# CH32V205 register map
Vendor: WCH Ltd.; File version: 1.0
Registers are 32-bit, read-write, reset 0x0 unless marked. A register's access mark holds for its fields unless they carry their own. Offsets are from the block's base; [hi:lo] are bit positions; {n}, {i} and the like mark numbered series.

## FLASH
Base 0x40022000
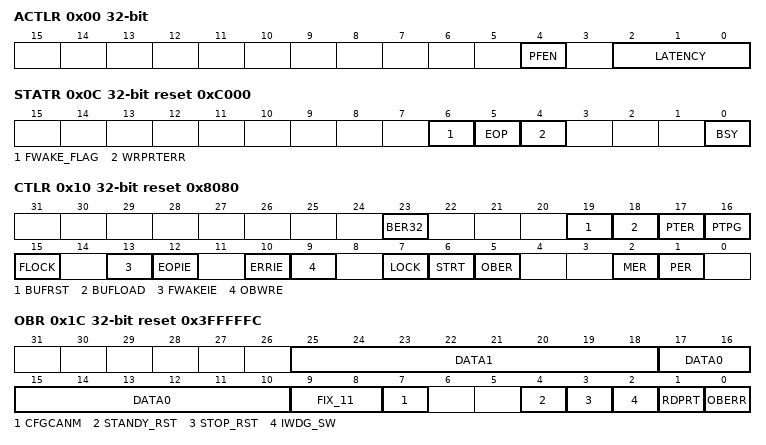
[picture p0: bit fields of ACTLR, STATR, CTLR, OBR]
0x00 ACTLR — Access control register
  [4] PFEN — prefetch enable
  [2:0] LATENCY — FLASH standby condition
0x04 KEYR wo reset 0x3FFFFFC — Flash key register
  [31:0] KEYR — FPEC key
0x08 OBKEYR wo — Flash option key register
  [31:0] OBTKEY — Option byte key
0x0C STATR access per field reset 0xC000 — Status register
  [6] FWAKE_FLAG rw — Wake-Up flag
  [5] EOP rw — End of operation
  [4] WRPRTERR rw — Write protection error
  [0] BSY ro — Busy
0x10 CTLR reset 0x8080 — Control register
  [23] BER32 — Block Erase 32K
  [19] BUFRST — BUF reset
  [18] BUFLOAD — Data buffer
  [17] PTER — Fast erase
  [16] PTPG — Fast programming
  [15] FLOCK — Fast programmable lock
  [13] FWAKEIE — wake-up interrupt enable
  [12] EOPIE — End of operation interrupt enable
  [10] ERRIE — Error interrupt enable
  [9] OBWRE — Option bytes write enable
  [7] LOCK
  [6] STRT — Start
  [5] OBER — Option byte erase
  [2] MER — Mass Erase
  [1] PER — Page Erase
0x14 ADDR wo — Flash address register
  [31:0] FAR — Flash Address
0x1C OBR ro reset 0x3FFFFFC — Option byte register
  [25:18] DATA1 — Data byte 1
  [17:10] DATA0 — Data byte 0
  [9:8] FIX_11 — Fixed to 11
  [7] CFGCANM — Configure the offline recovery time
  [4] STANDY_RST
  [3] STOP_RST
  [2] IWDG_SW
  [1] RDPRT — Read protection
  [0] OBERR — Option byte error
0x20 WPR ro — Write protection register
  [31:0] WRP — Write protect
0x24 MODEKEYR wo reset 0xFFE — Mode select register
  [31:0] MODEKEYR — Mode select

## PFIC — Programmable Fast Interrupt Controller
Base 0xE000E000
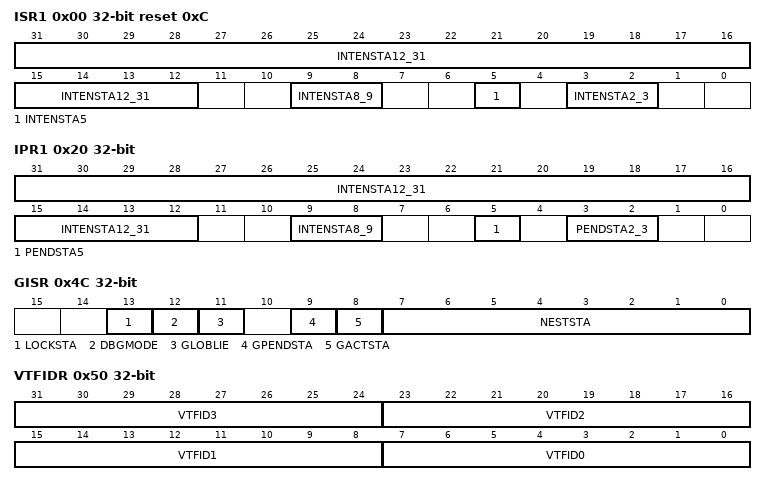
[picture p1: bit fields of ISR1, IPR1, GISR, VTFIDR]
0x00 ISR1 ro reset 0xC — Interrupt Status Register
  [31:12] INTENSTA12_31 — Interrupt ID Status
  [9:8] INTENSTA8_9 — Interrupt ID Status
  [5] INTENSTA5 — Interrupt ID Status
  [3:2] INTENSTA2_3 — Interrupt ID Status
0x04 ISR2 ro — Interrupt Status Register
  [31:0] INTENSTA — Interrupt ID Status
0x08 ISR3 ro — Interrupt Status Register
  [20:0] INTENSTA — Interrupt ID Status
0x20 IPR1 ro — Interrupt Pending Register
  [31:12] INTENSTA12_31 — PENDSTA
  [9:8] INTENSTA8_9 — PENDSTA
  [5] PENDSTA5 — PENDSTA
  [3:2] PENDSTA2_3 — PENDSTA
0x24 IPR2 ro — Interrupt Pending Register
  [31:0] PENDSTA
0x28 IPR3 ro — Interrupt Pending Register
  [20:0] PENDSTA
0x40 ITHRESDR — Interrupt Priority Register
  [7:0] THRESHOLD
0x4C GISR ro — Interrupt Global Register
  [13] LOCKSTA — lock-out state
  [12] DBGMODE — debug mode
  [11] GLOBLIE — global interrupt enable
  [9] GPENDSTA — interrupt pending
  [8] GACTSTA — interrupt execution
  [7:0] NESTSTA — interrupt nesting
0x50 VTFIDR — ID Config Register
  [8n+7:8n] VTFID{n} (n=0..3)
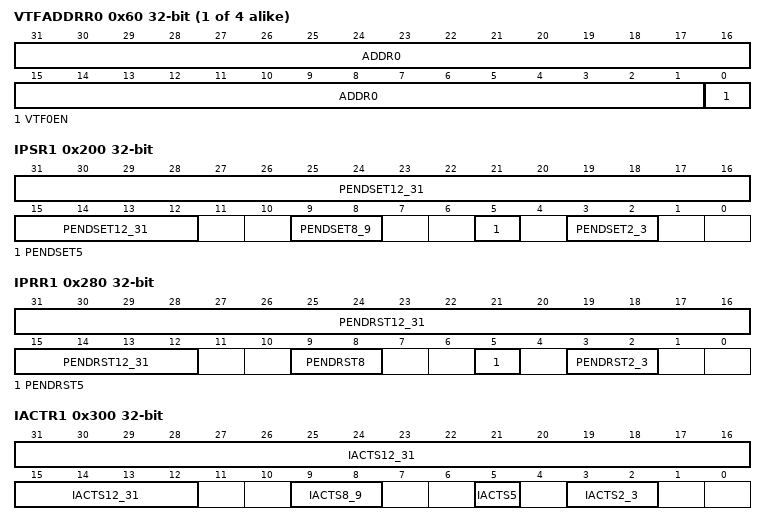
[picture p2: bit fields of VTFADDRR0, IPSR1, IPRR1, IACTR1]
{0x60+4i} VTFADDRR{i} (i=0..3) — Interrupt {i} address Register
  [31:1] ADDR{i}, [0] VTF{i}EN
0x100 IENR1 wo — Interrupt Setting Register
  [31:12] INTEN12_31
0x104 IENR2 wo — Interrupt Setting Register
  [31:0] INTEN — INTEN32_63
0x108 IENR3 wo — Interrupt Setting Register
  [20:0] INTEN — INTEN64_84
0x180 IRER1 wo — Interrupt Clear Register
  [31:12] INTRSET12_31
0x184 IRER2 wo — Interrupt Clear Register
  [31:0] INTRSET — INTRSET38_63
0x188 IRER3 wo — Interrupt Clear Register
  [20:0] INTRSET — INTRSET64_84
0x200 IPSR1 wo — Interrupt Pending Register
  [31:12] PENDSET12_31 — PENDSET
  [9:8] PENDSET8_9 — PENDSET
  [5] PENDSET5 — PENDSET
  [3:2] PENDSET2_3 — PENDSET
0x204 IPSR2 wo — Interrupt Pending Register
  [31:0] PENDSET — PENDSET32_63
0x208 IPSR3 wo — Interrupt Pending Register
  [20:0] PENDSET — PENDSET64_84
0x280 IPRR1 wo — Interrupt Pending Clear Register
  [31:12] PENDRST12_31 — PENDRESET
  [9:8] PENDRST8 — PENDRESET
  [5] PENDRST5 — PENDRESET
  [3:2] PENDRST2_3 — PENDRESET
0x284 IPRR2 wo — Interrupt Pending Clear Register
  [31:0] PENDRST — PENDRESET32_63
0x288 IPRR3 wo — Interrupt Pending Clear Register
  [20:0] PENDRST — PENDRESET64_84
0x300 IACTR1 wo — Interrupt ACTIVE Register
  [31:12] IACTS12_31 — IACTS
  [9:8] IACTS8_9 — IACTS
  [5] IACTS5 — IACTS
  [3:2] IACTS2_3 — IACTS
0x304 IACTR2 wo — Interrupt ACTIVE Register
  [31:0] IACTS — IACTS32_63
0x308 IACTR3 wo — Interrupt ACTIVE Register
  [31:0] IACTS — IACTS64_84
{0x400+4i} IPRIOR{i} (i=0..63) — Interrupt Priority Register
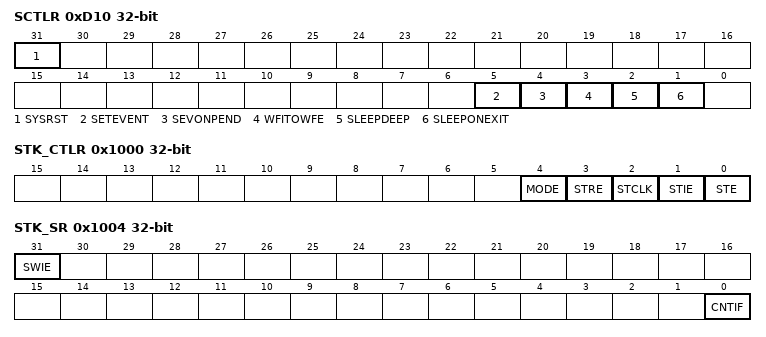
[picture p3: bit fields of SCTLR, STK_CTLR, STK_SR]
0xD10 SCTLR — System Control Register
  [31] SYSRST — System reset
  [5] SETEVENT
  [4] SEVONPEND
  [3] WFITOWFE — ues WFI as WFE
  [2] SLEEPDEEP — low power mode selection
  [1] SLEEPONEXIT — system leaves the state after an interruption
0x1000 STK_CTLR — System counter control register
  [4] MODE — Counting mode
  [3] STRE — System reload register
  [2] STCLK — System selects the clock source
  [1] STIE — System counter interrupt enable
  [0] STE — System counter enable
0x1004 STK_SR — System START
  [31] SWIE — System software triggered interrupts enable
  [0] CNTIF — count value comparsion flag
0x1008 STK_CNTL — System counter low register
  [31:0] CNT
0x1010 STK_CMPLR — System compare low register
  [31:0] CMP
